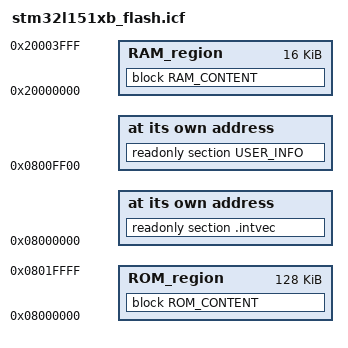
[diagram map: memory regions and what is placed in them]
/*###ICF### Section handled by ICF editor, don't touch! ****/
/*-Editor annotation file-*/
/* IcfEditorFile="$TOOLKIT_DIR$\config\ide\IcfEditor\cortex_v1_0.xml" */
/*-Specials-*/
define symbol __ICFEDIT_intvec_start__ = 0x08000000;
/*-Memory Regions-*/
define exported symbol __ICFEDIT_region_ROM_start__ = 0x08000000 ;
define exported symbol __ICFEDIT_region_ROM_end__   = 0x0801FFFF;
define exported symbol __ICFEDIT_region_RAM_start__ = 0x20000000;
define exported symbol __ICFEDIT_region_RAM_end__   = 0x20003FFF;
/*-Sizes-*/
define symbol __ICFEDIT_size_cstack__ = 0x400;
define symbol __ICFEDIT_size_heap__   = 0x200;
/**** End of ICF editor section. ###ICF###*/


define memory mem with size = 4G;
define region ROM_region   = mem:[from __ICFEDIT_region_ROM_start__   to __ICFEDIT_region_ROM_end__];
define region RAM_region   = mem:[from __ICFEDIT_region_RAM_start__   to __ICFEDIT_region_RAM_end__];

define block CSTACK    with alignment = 8, size = __ICFEDIT_size_cstack__   { };
define block HEAP      with alignment = 8, size = __ICFEDIT_size_heap__     { };

define exported symbol __ICFEDIT_region_USER_INFO_ADDR__   = __ICFEDIT_region_ROM_start__  + ((__ICFEDIT_region_ROM_end__ - __ICFEDIT_region_ROM_start__ )/ 2) + 1 - 256;
place at address mem:__ICFEDIT_region_USER_INFO_ADDR__ { readonly section USER_INFO };

//define symbol __ICFEDIT_region_USER_DATA_ADDR__   = 0x08050000;
//place at address mem:__ICFEDIT_region_USER_DATA_ADDR__ { readonly section USER_DATA };

place at address mem:__ICFEDIT_intvec_start__ { readonly section .intvec };

define block ROM_CONTENT with fixed order
{
	//readonly section checksum,
	//readonly section ROM_length_used,
	//readonly section checksum_start_mark,
	readonly,
	//readonly section checksum_end_mark
};

initialize by copy { readwrite };
do not initialize  { section .noinit };

define block RAM_CONTENT with fixed order
{
	section .noinit, 
			readwrite, 
    section .bss, 
    block 	HEAP, 
    block 	CSTACK
};

//keep { section .intvec };
//keep { section .bss };

place in ROM_region   { block ROM_CONTENT};
place in RAM_region   { block RAM_CONTENT};
